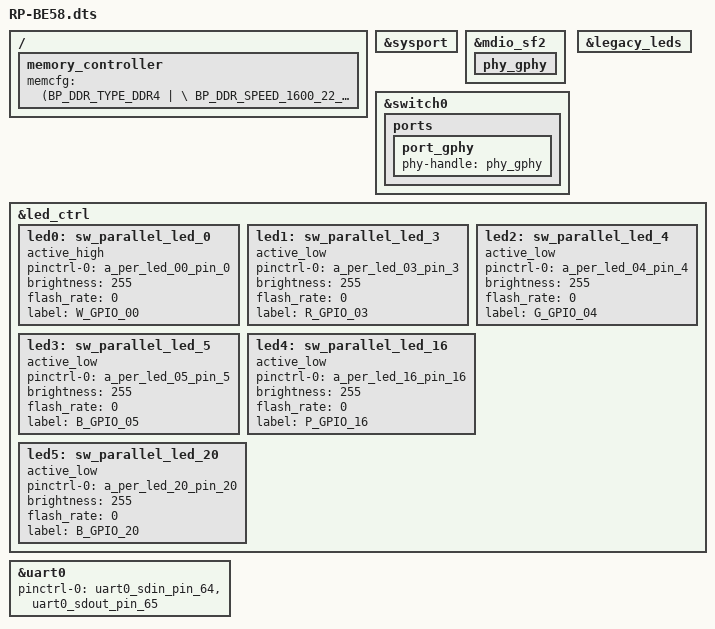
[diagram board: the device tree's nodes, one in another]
#include "6764.dtsi"

/ {
	memory_controller {
		memcfg = <(BP_DDR_TYPE_DDR4       | \
			BP_DDR_SPEED_1600_22_22_22     | \
			BP_DDR_TOTAL_SIZE_512MB       | \
			BP_DDR_DEVICE_WIDTH_16        | \
			BP_DDR_TOTAL_WIDTH_16BIT      | \
			BP_DDR_6764_DEFAULT           | \
			BP_DDR_CONFIG_DEBUG)>;
	};
/*
	buttons {
		compatible = "brcm,buttons";
		reset_button {
			ext_irq = <&bca_extintr 39 GPIO_ACTIVE_LOW (BCA_EXTINTR_TYPE_LOW_LEVEL | BCA_EXTINTR_TYPE_SENSE_EDGE)>;
			press {
				print = "Button Press -- Hold for 5s to do restore to default";
			};
			hold {
				rst_to_dflt = <5>;
			};
			release {
				reset = <0>;
			};
		};
		ses_button {
			ext_irq = <&bca_extintr 12 GPIO_ACTIVE_LOW (BCA_EXTINTR_TYPE_LOW_LEVEL | BCA_EXTINTR_TYPE_SENSE_EDGE)>;
			release {
				ses_short_period = <0>;
				ses_long_period = <3>;
			};
		};
	};
*/
};

&sysport {
};

&mdio_sf2 {
	/* Port PHY mapping:
        port_imp -8#0- port_gphy <----> phy_gphy
	 */
	phy_gphy {
		status = "okay";
	};
};

&switch0 {

	ports {
		port_gphy {
			phy-handle = <&phy_gphy>;
			status = "okay";
		};
	};
};

&legacy_leds {
};

&led_ctrl {

    led0: sw_parallel_led_0 {
        active_high;
        pinctrl-0 = <&a_per_led_00_pin_0>;
        brightness = <255>;
        flash_rate = <0>;
        status = "okay";
        label = "W_GPIO_00";
    };

    led1: sw_parallel_led_3 {
        active_low;
        pinctrl-0 = <&a_per_led_03_pin_3>;
        brightness = <255>;
        flash_rate = <0>;
        status = "okay";
        label = "R_GPIO_03";
    };

    led2: sw_parallel_led_4 {
        active_low;
        pinctrl-0 = <&a_per_led_04_pin_4>;
        brightness = <255>;
        flash_rate = <0>;
        status = "okay";
        label = "G_GPIO_04";
    };

    led3: sw_parallel_led_5 {
        active_low;
        pinctrl-0 = <&a_per_led_05_pin_5>;
        brightness = <255>;
        flash_rate = <0>;
        status = "okay";
        label = "B_GPIO_05";
    };

    led4: sw_parallel_led_16 {
        active_low;
        pinctrl-0 = <&a_per_led_16_pin_16>;
        brightness = <255>;
        flash_rate = <0>;
        status = "okay";
        label = "P_GPIO_16";
    };

    led5: sw_parallel_led_20 {
        active_low;
        pinctrl-0 = <&a_per_led_20_pin_20>;
        brightness = <255>;
        flash_rate = <0>;
        status = "okay";
        label = "B_GPIO_20";
    };
};

&uart0 {
	pinctrl-names = "default";
	pinctrl-0 = <&uart0_sdin_pin_64 &uart0_sdout_pin_65>;
	status = "okay";
};
